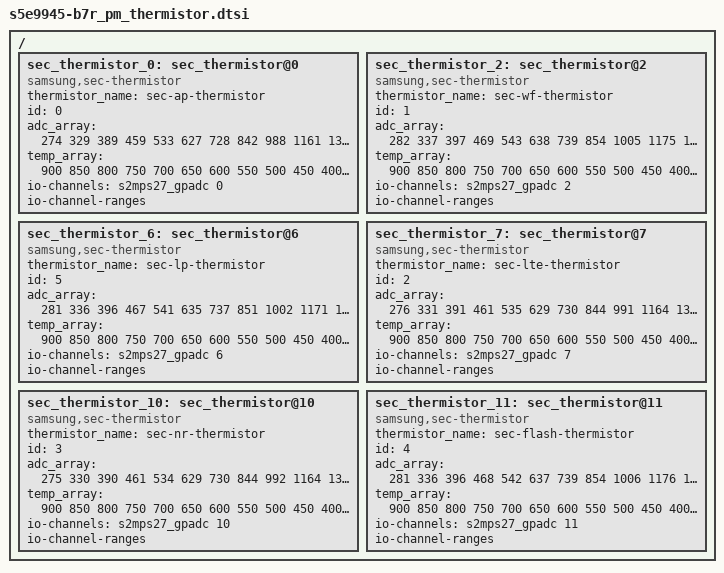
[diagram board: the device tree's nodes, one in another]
/*
 * SAMSUNG S5E9945 Power Management device tree source
 *
 * Copyright (c) 2024 Samsung Electronics Co., Ltd.
 *		http://www.samsung.com
 *
 * This program is free software; you can redistribute it and/or modify
 * it under the terms of the GNU General Public License version 2 as
 * published by the Free Software Foundation.
 */

/ {
	fragment@model {
		target-path = "/";
		__overlay__ {
			sec_thermistor_0: sec_thermistor@0 {
				compatible = "samsung,sec-thermistor";
				status = "okay";
				thermistor_name = "sec-ap-thermistor";
				id = <0>;

				adc_array = <274 329 389 459 533 627 728 842 988 1161
					1352 1557 1757 1973 2200 2444 2682 2911 3138 3329
					3480 3599 3705>;

				temp_array = <900 850 800 750 700 650 600 550 500 450
					  400 350 300 250 200 150 100 50 0 (-50)
					  (-100) (-150) (-200)>;

				io-channels = <&s2mps27_gpadc 0>;
				io-channel-names = "adc-ap-temp";
				io-channel-ranges;
			};

			sec_thermistor_2: sec_thermistor@2 {
				compatible = "samsung,sec-thermistor";
				status = "okay";
				thermistor_name = "sec-wf-thermistor";
				id = <1>;

				adc_array = <282 337 397 469 543 638 739 854 1005 1175
					1365 1571 1773 1988 2214 2458 2695 2922 3147 3336
					3485 3602 3707>;

				temp_array = <900 850 800 750 700 650 600 550 500 450
					  400 350 300 250 200 150 100 50 0 (-50)
					  (-100) (-150) (-200)>;

				io-channels = <&s2mps27_gpadc 2>;
				io-channel-names = "adc-wf-temp";
				io-channel-ranges;
			};

			sec_thermistor_6: sec_thermistor@6 {
				compatible = "samsung,sec-thermistor";
				status = "okay";
				thermistor_name = "sec-lp-thermistor";
				id = <5>;

				adc_array = <281 336 396 467 541 635 737 851 1002 1171
					1361 1566 1767 1983 2209 2453 2691 2917 3143 3332
					3482 3599 3704>;

				temp_array = <900 850 800 750 700 650 600 550 500 450
					  400 350 300 250 200 150 100 50 0 (-50)
					  (-100) (-150) (-200)>;

				io-channels = <&s2mps27_gpadc 6>;
				io-channel-names = "adc-lp-temp";
				io-channel-ranges;
			};

			sec_thermistor_7: sec_thermistor@7 {
				compatible = "samsung,sec-thermistor";
				status = "okay";
				thermistor_name = "sec-lte-thermistor";
				id = <2>;

				adc_array = <276 331 391 461 535 629 730 844 991 1164
					1355 1560 1762 1978 2205 2449 2688 2916 3143 3334
					3484 3601 3707>;

				temp_array = <900 850 800 750 700 650 600 550 500 450
					  400 350 300 250 200 150 100 50 0 (-50)
					  (-100) (-150) (-200)>;

				io-channels = <&s2mps27_gpadc 7>;
				io-channel-names = "adc-lte-temp";
				io-channel-ranges;
			};

			sec_thermistor_10: sec_thermistor@10 {
				compatible = "samsung,sec-thermistor";
				status = "okay";
				thermistor_name = "sec-nr-thermistor";
				id = <3>;

				adc_array = <275 330 390 461 534 629 730 844 992 1164
					1356 1562 1763 1980 2207 2452 2689 2918 3144 3336
					3485 3603 3708>;

				temp_array = <900 850 800 750 700 650 600 550 500 450
					  400 350 300 250 200 150 100 50 0 (-50)
					  (-100) (-150) (-200)>;

				io-channels = <&s2mps27_gpadc 10>;
				io-channel-names = "adc-nr-temp";
				io-channel-ranges;
			};

			sec_thermistor_11: sec_thermistor@11 {
				compatible = "samsung,sec-thermistor";
				status = "okay";
				thermistor_name = "sec-flash-thermistor";
				id = <4>;

				adc_array = <281 336 396 468 542 637 739 854 1006 1176
					1367 1574 1779 1994 2221 2466 2705 2932 3156 3348
					3494 3611 3716>;

				temp_array = <900 850 800 750 700 650 600 550 500 450
					  400 350 300 250 200 150 100 50 0 (-50)
					  (-100) (-150) (-200)>;

				io-channels = <&s2mps27_gpadc 11>;
				io-channel-names = "adc-flash-temp";
				io-channel-ranges;
			};
		}; /* end of __overlay__ */
	}; /* end of fragment */
}; /* end of root */
